# SN32F400 register map
Vendor: SONiX Technology Co., Ltd.; Series: SN32F400; File version: 1.1
CPU: CM0 r0p0, little endian, no MPU, no FPU, 2 interrupt priority bits
Registers are 32-bit, read-write, reset 0x0 unless marked. A register's access mark holds for its fields unless they carry their own. Offsets are from the block's base; [hi:lo] are bit positions; {n}, {i} and the like mark numbered series.

## SN_ADC — ADC
Base 0x40026000
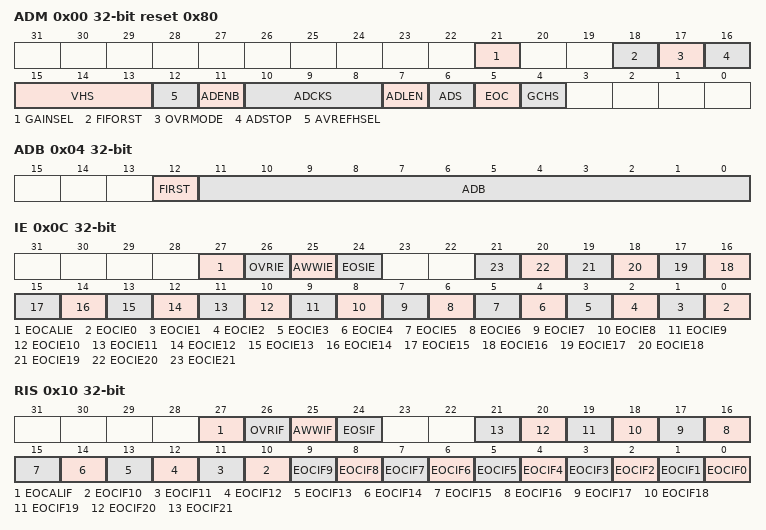
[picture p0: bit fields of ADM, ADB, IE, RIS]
0x00 ADM reset 0x80 — Offset:0x00 ADC Management register
  [21] GAINSEL — VREF gain select bit
    0=Low (Low gain); 1=High gain
  [18] FIFORST wo — ADB FIFO Reset bit
    0=No (No effect); 1=Reset ADB FIFO
  [17] OVRMODE — Overrun mode select bit
    0=Preserve (The old data is preserved when the overrun occurs); 1=Overwrite (The ADC data FIFO is overwritted with the latest data)
  [16] ADSTOP — ADC stop control bit
    0=No (No effect); 1=Stop (ADC stops converting)
  [15:13] VHS — Internal Ref. voltage source
    0=000b (Internal 2.0V as ADC internal reference voltage); 1=001b (Internal 3.0V as ADC internal reference voltage); 2=010b (Internal 4.5V as ADC internal reference voltage); 3=011b (Internal 1.5V as ADC internal reference voltage); 4=100b (VDD as ADC internal reference voltage, Internal 2.0V as AIN18); 5=101b (VDD as ADC internal reference voltage, Internal 3.0V as AIN18); 6=110b (VDD as ADC internal reference voltage, Internal 4.5V as AIN18); 7=111b (VDD as ADC internal reference voltage, Internal 1.5V as AIN18)
  [12] AVREFHSEL — ADC high reference voltage source
    0=Interal VDD (P2.0 acts as GPIO or AIN0 pin); 1=External reference voltage (P2.0 acts as AVREFH pin)
  [11] ADENB — ADC enable
    0=Disable ADC; 1=Enable ADC
  [10:8] ADCKS — ADC clock source divider
    0=000b (ADC_PCLK/1); 1=001b (ADC_PCLK/2); 2=010b (ADC_PCLK/4); 3=011b (ADC_PCLK/8); 4=100b (ADC_PCLK/16); 5=101b (ADC_PCLK/32)
  [7] ADLEN — ADC resolution
    0=8-bit ADB; 1=12-bit ADB
  [6] ADS — ADC start control
    0=Stop (ADC stops); 1=Start ADC conversion
  [5] EOC ro — ADC status
    0=Busy (ADC is processing); 1=End (End of processing)
  [4] GCHS — ADC global channel enable
    0=Disable AIN channel; 1=Enable AIN channel
0x04 ADB ro — Offset:0x04 ADC Data register
  [12] FIRST — First ADB of Multiple channels
    0=Not first ADB of Multiple channels; 1=First ADB of Multiple channels
  [11:0] ADB — ADB11~ADB4 bits for 8-bit ADC, ADB11~ADB0 bits for 12-bit ADC
0x0C IE — Offset:0x0C ADC Interrupt Enable register
  [27] EOCALIE — End of calibration interrupt enable
    0=Disable EOC interrupt; 1=Enable (EOC interrupt is triggered when the end of calibration happens)
  [26] OVRIE — ADC Overrun interrupt enable
    0=Disable OVR interrupt; 1=Enable (ADC interrupt is triggered when ADB overrun happens)
  [25] AWWIE — ADC Window watchdog interrupt enable
    0=Disable AWW interrupt; 1=Enable (ADC interrupt is triggered when ADB meets AWW condition)
  [24] EOSIE — EOS interrupt enable
    0=Disable EOS interrupt; 1=Enable (ADC interrupt is triggered when all channels in a sequence completes ADC conversion)
  [n] EOCIE{n} (n=0..21) — AIN{n} EOC interrupt enable
    0=Disable AIN{n} EOC interrupt; 1=Enable (ADC interrupt is triggered when AIN{n} completes ADC conversion)
0x10 RIS ro — Offset:0x10 ADC Raw Interrupt Status register
  [27] EOCALIF — End of calibration raw interrupt flag
    0=No interrupt requirement met; 1=Met interrupt requirements (ADC end of calibration)
  [26] OVRIF — Overrun interrupt flag
    0=No interrupt requirement met; 1=Met interrupt requirements (ADB FIFO overrun)
  [25] AWWIF — ADC Window Watchdog interrupt flag
    0=No interrupt requirement met; 1=Met interrupt requirements (ADB matches AWW condition)
  [24] EOSIF — End of sequence interrupt flag
    0=No interrupt (No sequence of conversion is completed); 1=Met interrupt requirements (All channels of a sequence are converted)
  [n] EOCIF{n} (n=0..21) — AIN{n} interrupt flag
    0=No interrupt on AIN{n}; 1=Met interrupt requirements (AIN{n} completes ADC conversion)
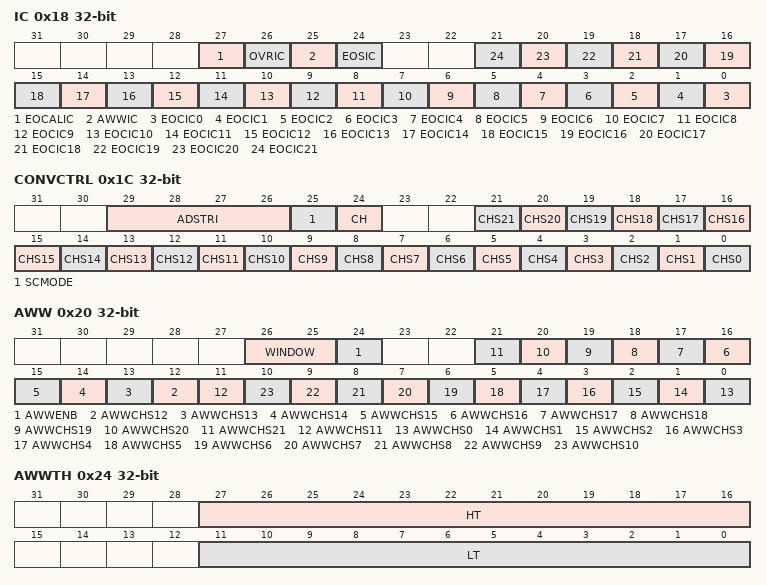
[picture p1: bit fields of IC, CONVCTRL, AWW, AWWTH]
0x18 IC wo — Offset:0x18 ADC Interrupt Clear register
  [27] EOCALIC — End of calibration interrupt clear bit
    0=No (No effect); 1=Clear EOCALIF bit
  [26] OVRIC — Overrun interrupt flag clear bit
    0=No (No effect); 1=Clear OVRIF bit
  [25] AWWIC — ADC Window Watchdog interrupt flag clear bit
    0=No (No effect); 1=Clear AWWIF bit
  [24] EOSIC — End of sequence interrupt flag clear bit
    0=No (No effect); 1=Clear EOSIF bit
  [n] EOCIC{n} (n=0..21) — AIN{n} interrupt flag clear bit
    0=No (No effect); 1=Clear EOCIF{n} bit
0x1C CONVCTRL — Offset:0x1C ADC Convert Control register
  [29:26] ADSTRI — ADC start conversion trigger source selection
    0=0000b (ADS bit (Software mode)); 1=0001b (CT16B0 MR0IF rising edge); 2=0010b (CT16B0 MR1IF rising edge); 3=0011b (CT16B0 MR2IF rising edge); 4=0100b (CT16B0 MR3IF rising edge); 5=0101b (CT16B0 MR9IF rising edge); 6=0110b (CT16B1 MR9IF rising edge); 10=1010b (CT16B5 MR9IF rising edge)
  [25] SCMODE — Single/Continuous mode
    0=Single mode; 1=Continuous mode
  [24] CH — Converting channel number
    0=Single channel; 1=Multiple channels
  [21] CHS21 — AIN21 select bit
    0=Not (AIN21 (OP2O) is not selected); 1=Convert AIN21 (OP2O)
  [20] CHS20 — AIN20 select bit
    0=Not (AIN20 (OP1O) is not selected); 1=Convert AIN20 (OP1O)
  [19] CHS19 — AIN19 select bit
    0=Not (AIN19 (OP0O) is not selected); 1=Convert AIN19 (OP0O)
  [18] CHS18 — AIN18 select bit
    0=Not (AIN18 (Internal reference voltage) is not selected); 1=Convert AIN18 (Internal reference voltage)
  [17] CHS17 — AIN17 select bit
    0=Not (AIN17 (VSS) is not selected); 1=Convert AIN17 (VSS)
  [16] CHS16 — AIN16 select bit
    0=Not (AIN16 (VDD) is not selected); 1=Convert AIN16 (VDD)
  [n] CHS{n} (n=0..15) — AIN{n} select bit
    0=Not (AIN{n} is not selected); 1=Convert AIN{n}
0x20 AWW — Offset:0x20 ADC Window Watchdog register
  [26:25] WINDOW — AWW window selection bits
    0=More (ADB is more than AWW high threshold); 1=Between (ADB is between AWW high threshold and low threshold); 2=Less (ADB is less than AWW low threshold)
  [24] AWWENB — ADC Window watchdog enable bit
    0=Disable AWW; 1=Enable AWW
  [n] AWWCHS{n} (n=12..21) — AIN{n} Window watchdog select bit
    0=Disable AWW for AIN{n}; 1=Enable AWW for AIN{n}
  [11] AWWCHS11 — AIN1 Window watchdog select bit
    0=Disable AWW for AIN11; 1=Enable AWW for AIN11
  [n] AWWCHS{n} (n=0..10) — AIN{n} Window watchdog select bit
    0=Disable AWW for AIN{n}; 1=Enable AWW for AIN{n}
0x24 AWWTH — Offset:0x24 ADC Window Watchdog Threshold register
  [27:16] HT — AWW window High threshold value
  [11:0] LT — AWW window Low threshold value
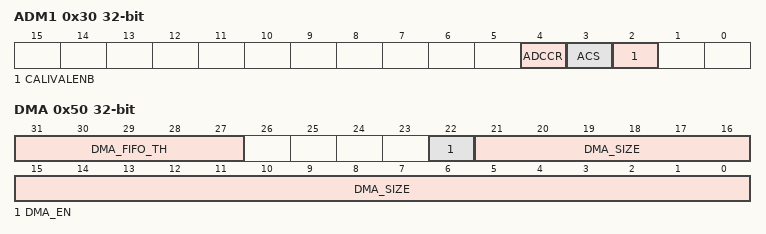
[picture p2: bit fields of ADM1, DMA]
0x30 ADM1 (reset mask 0xC) — Offset:0x30 ADC Management register 1
  [4] ADCCR — ADC Conversion current bit
    0=Disable (ADC clock up to 16MHz); 1=Enable (ADC clock up to 4MHz, reduce the power consumption)
  [3] ACS — ADC Calibration start bit
    0=Stop (ADC calibration stops); 1=Start ADC calibration
  [2] CALIVALENB — ADC Calibration value enable bit
    0=Disable (ADC conversion without calibration value); 1=Enable (ADC conversion with calibration value)
0x34 CALIST ro — Offset:0x34 ADC Csalibration Status register
  [0] CAL_ERR — ADC calibration error
    0=None (No error in ADC calibration period); 1=Error occurs in ADC calibration period
0x50 DMA — Offset:0x50 ADC DMA mode register
  [31:27] DMA_FIFO_TH — ADC FIFO Threshold level
    0=00000b (RX FIFO threshold level = 0); 1=00001b (RX FIFO threshold level = 1); 2=00010b (RX FIFO threshold level = 2); 3=00011b (RX FIFO threshold level = 3); 4=00100b (RX FIFO threshold level = 4); 5=00101b (RX FIFO threshold level = 5); 6=0110b (RX FIFO threshold level = 6); 7=00111b (RX FIFO threshold level = 7); 8=01000b (RX FIFO threshold level = 8); 9=01001b (RX FIFO threshold level = 9); 10=01010b (RX FIFO threshold level = 10); 11=01011b (RX FIFO threshold level = 11); 12=01100b (RX FIFO threshold level = 12); 13=01101b (RX FIFO threshold level = 13); 14=01110b (RX FIFO threshold level = 14); 15=01111b (RX FIFO threshold level = 15); 16=10000b (RX FIFO threshold level = 16 (FIFO Full))
  [22] DMA_EN — ADC DMA mode enable
    0=Disable ADC DMA mode; 1=Enable ADC DMA mode
  [21:0] DMA_SIZE — ADC DMA transfer size
